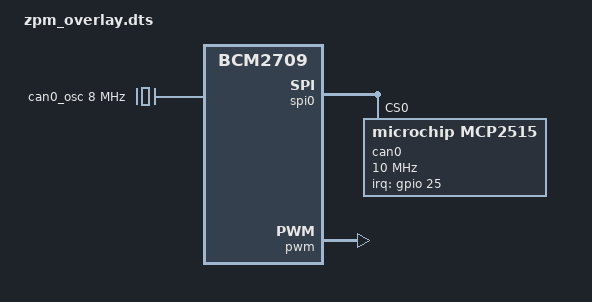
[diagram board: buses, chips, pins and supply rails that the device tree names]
/*
 * Device tree overlay for mcp251x/can0 on spi0.0
 */

/dts-v1/;
/plugin/;

/ {
    compatible = "brcm,bcm2835", "brcm,bcm2836", "brcm,bcm2708", "brcm,bcm2709";
    /* disable spi-dev for spi0.0 */
    fragment@0 {
        target = <&spi0>;
        __overlay__ {
            status = "okay";
        };
    };

    fragment@1 {
        target = <&spidev0>;
        __overlay__ {
            status = "disabled";
        };
    };

    /* the interrupt pin of the can-controller */
    fragment@2 {
        target = <&gpio>;
        __overlay__ {
            can0_pins: can0_pins {
                brcm,pins = <25>;
                brcm,function = <0>; /* input */
            };
        };
    };

    /* the clock/oscillator of the can-controller */
    fragment@3 {
        target-path = "/clocks";
        __overlay__ {
            /* external oscillator of mcp2515 on SPI0.0 */
            can0_osc: can0_osc {
                compatible = "fixed-clock";
                #clock-cells = <0>;
                clock-frequency  = <8000000>;
            };
        };
    };

    /* the spi config of the can-controller itself binding everything together */
    fragment@4 {
        target = <&spi0>;
        __overlay__ {
            /* needed to avoid dtc warning */
            #address-cells = <1>;
            #size-cells = <0>;
            can0: mcp2515@0 {
                reg = <0>;
                compatible = "microchip,mcp2515";
                pinctrl-names = "default";
                pinctrl-0 = <&can0_pins>;
                spi-max-frequency = <10000000>;
                interrupt-parent = <&gpio>;
                interrupts = <25 8>; /* IRQ_TYPE_LEVEL_LOW */
                clocks = <&can0_osc>;
		spi-cpol = <1>;
		spi-cpha = <1>;
            };
        };
    };
    
    fragment@5 {
	target = <&gpio>;
	__overlay__ {
		pwm_pins: pwm_pins {
			brcm,pins = <12 13>;
			brcm,function = <4 4>; /* Alt0 */
		};
	};
    };

    fragment@6 {
	target = <&pwm>;
	frag6: __overlay__ {
		pinctrl-names = "default";
		pinctrl-0 = <&pwm_pins>;
		assigned-clock-rates = <100000000>;
		status = "okay";
	};
    };

   
};
